# RE01_1500KB register map
Vendor: Renesas Electronics Corporation; Series: RE01_1500KB; File version: 1.20
CPU: CM0PLUS r0p1, little endian, MPU, no FPU, VTOR, 2 interrupt priority bits
Registers are 8-bit, read-write, reset 0x0 unless marked. A register's access mark holds for its fields unless they carry their own. Offsets are from the block's base; [hi:lo] are bit positions; {n}, {i} and the like mark numbered series.

## SPI0 — Serial Peripheral Interface 0
Base 0x40072000
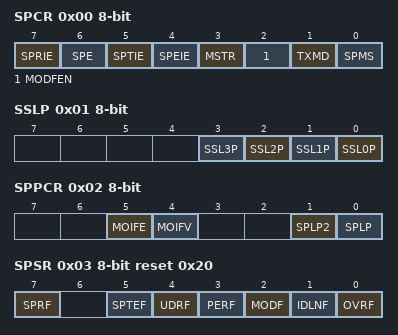
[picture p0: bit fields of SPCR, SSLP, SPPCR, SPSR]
0x00 SPCR — SPI Control Register
  [7] SPRIE — SPI Receive Buffer Full Interrupt Enable
    0=Disables the generation of SPI receive buffer full interrupt requests; 1=Enables the generation of SPI receive buffer full interrupt requests
  [6] SPE — SPI Function Enable
    0=Disables the SPI function; 1=Enables the SPI function
  [5] SPTIE — Transmit Buffer Empty Interrupt Enable
    0=Disables the generation of transmit buffer empty interrupt requests; 1=Enables the generation of transmit buffer empty interrupt requests
  [4] SPEIE — SPI Error Interrupt Enable
    0=Disables the generation of SPI error interrupt requests; 1=Enables the generation of SPI error interrupt requests
  [3] MSTR — SPI Master/Slave Mode Select
    0=Slave mode; 1=Master mode
  [2] MODFEN — Mode Fault Error Detection Enable
    0=Disables the detection of mode fault error; 1=Enables the detection of mode fault error
  [1] TXMD — Communications Operating Mode Select
    0=Full-duplex synchronous serial communications; 1=Serial communications consisting of only transmit operations
  [0] SPMS — SPI Mode Select
    0=SPI operation (4-wire method); 1=Clock synchronous operation (3-wire method)
0x01 SSLP — SPI Slave Select Polarity Register
  [n] SSL{n}P (n=0..3) — SSL{n} Signal Polarity Setting
    0=SSL{n} signal is active low; 1=SSL{n} signal is active high
0x02 SPPCR — SPI Pin Control Register
  [5] MOIFE — MOSI Idle Value Fixing Enable
    0=MOSI output value equals final data from previous transfer; 1=MOSI output value equals the value set in the MOIFV bit
  [4] MOIFV — MOSI Idle Fixed Value
    0=The level output on the MOSIn pin during MOSI idling corresponds to low; 1=The level output on the MOSIn pin during MOSI idling corresponds to high
  [1] SPLP2 — SPI Loopback 2
    0=Normal mode; 1=Loopback mode (data is not inverted for transmission)
  [0] SPLP — SPI Loopback
    0=Normal mode; 1=Loopback mode (data is inverted for transmission)
0x03 SPSR reset 0x20 — SPI Status Register
  [7] SPRF — SPI Receive Buffer Full Flag
    0=No valid data in SPDR/SPDR_HA; 1=Valid data found in SPDR/SPDR_HA
  [5] SPTEF — SPI Transmit Buffer Empty Flag
    0=Data found in the transmit buffer; 1=No data in the transmit buffer
  [4] UDRF — Underrun Error Flag(When MODF is 0, This bit is invalid.)
    0=A mode fault error occurs (MODF=1); 1=An underrun error occurs (MODF=1)
  [3] PERF — Parity Error Flag
    0=No parity error occurs; 1=A parity error occurs
  [2] MODF — Mode Fault Error Flag
    0=Neither mode fault error nor underrun error occurs; 1=A mode fault error or an underrun error occurs
  [1] IDLNF ro — SPI Idle Flag
    0=SPI is in the idle state; 1=SPI is in the transfer state
  [0] OVRF — Overrun Error Flag
    0=No overrun error occurs; 1=An overrun error occurs
0x04 SPDR 32-bit — SPI Data Register
  [31:0] SPDR — SPDR is the interface with the buffers that hold data for transmission and reception by the RSPI.When accessing in word (SPDCR.SPLW=1), access SPDR.
0x04 SPDR_HA 16-bit (alternate view of SPDR) — SPI Data Register ( halfword access )
  [15:0] SPDR_HA — SPDR is the interface with the buffers that hold data for transmission and reception by the SPI.When accessing in halfword (SPDCR.SPLW=0), access SPDR_HA.
0x04 SPDR_HH (alternate view of SPDR) — SPI Data Register ( byte access )
0x08 SPSCR — SPI Sequence Control Register
  [2:0] SPSLN
    {v}={v+1} - (v=0..7)
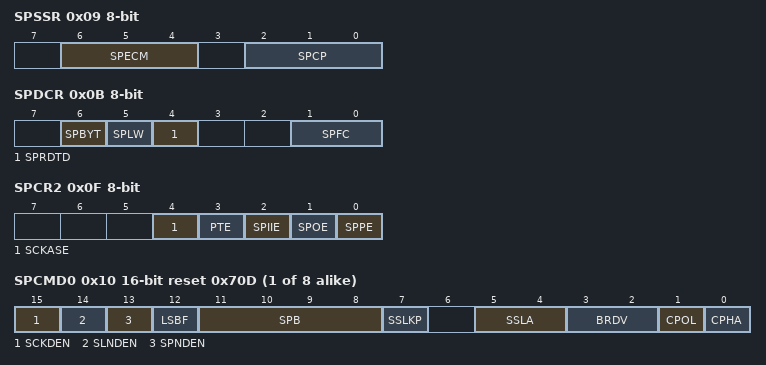
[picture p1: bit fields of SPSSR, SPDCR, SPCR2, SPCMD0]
0x09 SPSSR — SPI Sequence Status Register
  [6:4] SPECM ro
    {v}=SPCMD{v} (v=0..7)
  [2:0] SPCP
    {v}=SPCMD{v} (v=0..7)
0x0A SPBR reset 0xFF — SPI Bit Rate Register
  [7:0] SPBR — SPBR sets the bit rate in master mode.
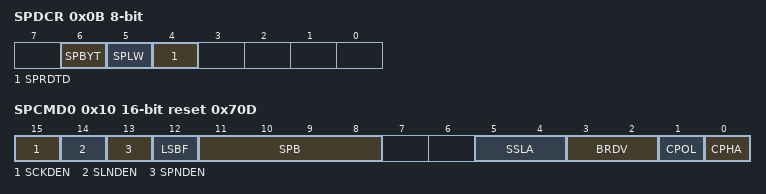
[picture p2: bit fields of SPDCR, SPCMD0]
0x0B SPDCR — SPI Data Control Register
  [6] SPBYT
  [5] SPLW — SPI Word Access/Halfword Access Specification
    0=Set SPDR_HA to valid for halfword access; 1=Set SPDR to valid for word access
  [4] SPRDTD — SPI Receive/Transmit Data Selection
    0=SPDR/SPDR_HA values are read from the receive buffer; 1=SPDR/SPDR_HA values are read from the transmit buffer (but only if the transmit buffer is empty)
  [1:0] SPFC
    {v}={v+1}frame (v=0..3)
0x0C SPCKD — SPI Clock Delay Register
  [2:0] SCKDL — RSPCK Delay Setting
    {v}={v+1} RSPCK (v=0..7)
0x0D SSLND — SPI Slave Select Negation Delay Register
  [2:0] SLNDL — SSL Negation Delay Setting
    {v}={v+1} RSPCK (v=0..7)
0x0E SPND — SPI Next-Access Delay Register
  [2:0] SPNDL — SPI Next-Access Delay Setting
    {v}={v+1} RSPCK + 2 PCLKB (v=0..7)
0x0F SPCR2 — SPI Control Register 2
  [4] SCKASE — RSPCK Auto-Stop Function Enable
    0=Disables the RSPCK auto-stop function; 1=Enables the RSPCK auto-stop function
  [3] PTE — Parity Self-Testing
    0=Disables the self-diagnosis function of the parity circuit; 1=Enables the self-diagnosis function of the parity circuit
  [2] SPIIE — SPI Idle Interrupt Enable
    0=Disables the generation of idle interrupt requests; 1=Enables the generation of idle interrupt requests
  [1] SPOE — Parity Mode
    0=Selects even parity for use in transmission and reception; 1=Selects odd parity for use in transmission and reception
  [0] SPPE — Parity Enable
    0=Does not add the parity bit to transmit data and does not check the parity bit of receive data; 1=Adds the parity bit to transmit data and checks the parity bit of receive data (when SPCR.TXMD = 0) / Adds the parity bit to transmit data but does not check the parity bit of receive data (when SPCR.TXMD = 1)
{0x10+2i} SPCMD{i} (i=0..7) 16-bit reset 0x70D — SPI Command Register 0~7
  [15] SCKDEN — RSPCK Delay Setting Enable
    0=An RSPCK delay of 1 RSPCK; 1=An RSPCK delay is equal to the setting of the SPI clock delay register (SPCKD)
  [14] SLNDEN — SSL Negation Delay Setting Enable
    0=An SSL negation delay of 1 RSPCK; 1=An SSL negation delay is equal to the setting of the SPI slave select negation delay register (SSLND)
  [13] SPNDEN — SPI Next-Access Delay Enable
    0=A next-access delay of 1 RSPCK + 2 PCLKB; 1=A next-access delay is equal to the setting of the SPI next-access delay register (SPND)
  [12] LSBF — SPI LSB First
    0=MSB first; 1=LSB first
  [11:8] SPB — SPI Data Length Setting
    {v}=8 bits (v=4..7); {v}={v+1} bits (v=8..15); 0=20 bits; 1=24 bits; 2=32 bits; 3=32 bits; other=others (Setting prohibited)
  [7] SSLKP
  [5:4] SSLA — SSL Signal Assertion Setting
    {v}=SSL{v} (v=0..3)
  [3:2] BRDV — Bit Rate Division Setting
    0=These bits select the base bit rate; 1=These bits select the base bit rate divided by 2; 2=These bits select the base bit rate divided by 4; 3=These bits select the base bit rate divided by 8
  [1] CPOL — RSPCK Polarity Setting
    0=RSPCK is low when idle; 1=RSPCK is high when idle
  [0] CPHA — RSPCK Phase Setting
    0=Data sampling on odd edge, data variation on even edge; 1=Data variation on odd edge, data sampling on even edge

## SPI1 — Serial Peripheral Interface 0
Base 0x40072100
Registers as SPI0, without SPSCR, SPSSR, SPCMD*; these are added or differ:
0x0B SPDCR — SPI Data Control Register
  [6] SPBYT
  [5] SPLW — SPI Word Access/Halfword Access Specification
    0=Set SPDR_HA to valid for halfword access; 1=Set SPDR to valid for word access
  [4] SPRDTD — SPI Receive/Transmit Data Selection
    0=SPDR/SPDR_HA values are read from the receive buffer; 1=SPDR/SPDR_HA values are read from the transmit buffer (but only if the transmit buffer is empty)
0x10 SPCMD0 16-bit reset 0x70D — SPI Command Register 0
  [15] SCKDEN — RSPCK Delay Setting Enable
    0=An RSPCK delay of 1 RSPCK; 1=An RSPCK delay is equal to the setting of the SPI clock delay register (SPCKD)
  [14] SLNDEN — SSL Negation Delay Setting Enable
    0=An SSL negation delay of 1 RSPCK; 1=An SSL negation delay is equal to the setting of the SPI slave select negation delay register (SSLND)
  [13] SPNDEN — SPI Next-Access Delay Enable
    0=A next-access delay of 1 RSPCK + 2 PCLKB; 1=A next-access delay is equal to the setting of the SPI next-access delay register (SPND)
  [12] LSBF — SPI LSB First
    0=MSB first; 1=LSB first
  [11:8] SPB — SPI Data Length Setting
    {v}=8 bits (v=4..7); {v}={v+1} bits (v=8..15); 0=20 bits; 1=24 bits; 2=32 bits; 3=32bits; other=others (Setting prohibited)
  [5:4] SSLA — SSL Signal Assertion Setting
    {v}=SSL{v} (v=0..3)
  [3:2] BRDV — Bit Rate Division Setting
    0=These bits select the base bit rate; 1=These bits select the base bit rate divided by 2; 2=These bits select the base bit rate divided by 4; 3=These bits select the base bit rate divided by 8
  [1] CPOL — RSPCK Polarity Setting
    0=RSPCK is low when idle; 1=RSPCK is high when idle
  [0] CPHA — RSPCK Phase Setting
    0=Data sampling on odd edge, data variation on even edge; 1=Data variation on odd edge, data sampling on even edge
